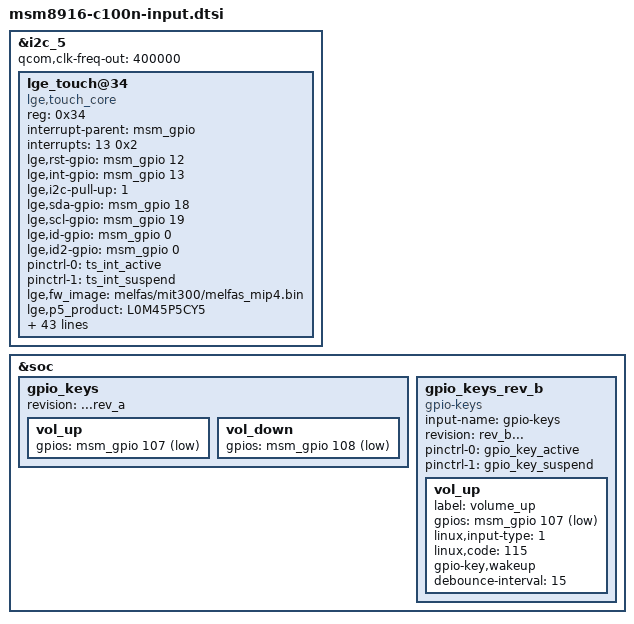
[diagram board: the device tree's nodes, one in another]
/* Copyright (c) 2012, Code Aurora Forum. All rights reserved.
 *
 * This program is free software; you can redistribute it and/or modify
 * it under the terms of the GNU General Public License version 2 and
 * only version 2 as published by the Free Software Foundation.
 *
 * This program is distributed in the hope that it will be useful,
 * but WITHOUT ANY WARRANTY; without even the implied warranty of
 * MERCHANTABILITY or FITNESS FOR A PARTICULAR PURPOSE.  See the
 * GNU General Public License for more details.
 */

&i2c_5 {
	qcom,clk-freq-out = <400000>;

	lge_touch@34 {
                status = "ok";
                compatible = "lge,touch_core";
                reg = <0x34>;
                interrupt-parent = <&msm_gpio>;
                interrupts = <13 0x2>;
                lge,rst-gpio    =       <&msm_gpio 12 0x00>;
                lge,int-gpio    =       <&msm_gpio 13 0x00>;
		lge,i2c-pull-up = 	<1>;
                lge,sda-gpio    =       <&msm_gpio 18 0x00>;
                lge,scl-gpio    =       <&msm_gpio 19 0x00>;
                lge,id-gpio     =       <&msm_gpio 0 0x00>;
                lge,id2-gpio    =       <&msm_gpio 0 0x00>;

                pinctrl-names = "pmx_ts_active","pmx_ts_suspend";               /*Touch GPIO pin name setting*/
                pinctrl-0 = <&ts_int_active>;       /*Touch GPIO pin active setting*/
                pinctrl-1 = <&ts_int_suspend>;   /*Touch GPIO pin suspend setting*/

                lge,fw_image = "melfas/mit300/melfas_mip4.bin";
                lge,p5_product = "L0M45P5CY5";
                lge,p5_fw_image = "melfas/mit300/melfas_mip4.bin";

                /* IC Type. This should be matched with proper device. */
                /*      0 : MMS-100S Series. MMS-128S , MMS-134S */
                /*      1 : MMS-100A Series. MMS-136 , MMS-144 , MMS-152 */
                /*      2 : MIT-200. AIT(Advanced Incell Touch)*/
                lge,auto_fw_update = <1>;
                lge,ic_type = <2>;
                lge,maker = "Melfas";
                lge,product = "L0M45P1CY5";

                /* panel status check */
                openshort_enable = <1>;

                /* Limitation Value. */
                raw_data_max = <3500>; /*<42125>;*/
                raw_data_min = <1000>; /*<11394>;*/
                raw_data_margin = <0>; /*<1000>;*/
                raw_data_otp_min = <15000>;
                raw_data_otp_max = <39000>;
                open_short_max = <3500>;
                open_short_min = <1000>;
                slope_max = <150>;
                slope_min = <70>;

                /* platform_data->caps */
                button_support = <0>;
                button_name = <>;
                is_width_supported = <1>;
                is_pressure_supported = <1>;
                is_id_supported = <1>;
                max_width = <30>;
                max_pressure = <0xff>;
                max_id = <10>;
                x_max = <720>;
                y_max = <1280>;
                lcd_x = <720>;
                lcd_y = <1280>;
                operation_mode = <1>;
                key_type = <3>;
                report_mode = <0>;
                delta_pos_threshold = <0>;
                panel_id = "L", "?", "?", "?";

                /* platform_data->role */
                booting_delay = <50>;
                reset_delay = <5>;
                suspend_pwr = <0>;
                resume_pwr = <1>;
                ghost_detection_enable = <0>;
                use_crack_mode = <0>;
                active_area_gap = <24>;

                /* platform_data->pwr*/
                /* type 0: none(default) */
                /*      1: gpio */
                /*      2: regulator */
                /* name if type == 1, gpio active condition "low" or "high" */
                /*      if type == 2, sypply name for regulator */
                /* value if type == 1, gpio pin no. */
                /*       if type == 2, regulator voltage */

		vdd_type0 = <2>;
		vdd_name0 = "vdd";
		vdd_value0 = <3000000>;
		vdd-supply = <&pm8916_l16>;
        };
};

&soc {
	gpio_keys {
		revision = "...rev_a";
		vol_up {
			gpios = <&msm_gpio 107 0x1>;
		};
		vol_down {
			gpios = <&msm_gpio 108 0x1>;
		};
	};
	gpio_keys_rev_b {
		compatible = "gpio-keys";
		input-name = "gpio-keys";
		revision = "rev_b...";
		pinctrl-names = "tlmm_gpio_key_active","tlmm_gpio_key_suspend";
		pinctrl-0 = <&gpio_key_active>;
		pinctrl-1 = <&gpio_key_suspend>;

		vol_up {
			label = "volume_up";
			gpios = <&msm_gpio 107 0x1>;
			linux,input-type = <1>;
			linux,code = <115>;
			gpio-key,wakeup;
			debounce-interval = <15>;
		};

	};
};
